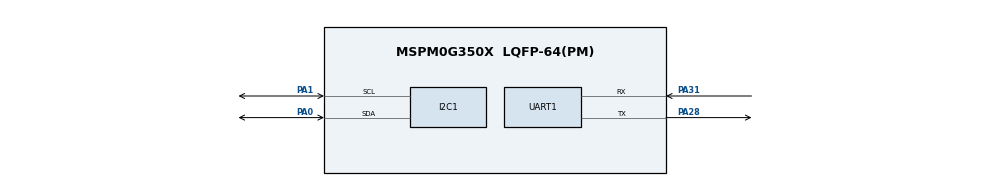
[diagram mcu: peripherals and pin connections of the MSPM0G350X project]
/**
 *
 * @cliArgs --device "MSPM0G350X" --part "Default" --package "LQFP-64(PM)" --product "mspm0_sdk@2.05.01.00"
 * @versions {"tool":"1.28.0+4696"}
 */

/**
 * Import the modules used in this configuration.
 */
const ADC12  = scripting.addModule("/ti/driverlib/ADC12", {}, false);
const ADC121 = ADC12.addInstance();
const GPIO   = scripting.addModule("/ti/driverlib/GPIO", {}, false);
const GPIO1  = GPIO.addInstance();
const GPIO2  = GPIO.addInstance();
const GPIO3  = GPIO.addInstance();
const GPIO4  = GPIO.addInstance();
const GPIO5  = GPIO.addInstance();
const GPIO6  = GPIO.addInstance();
const I2C    = scripting.addModule("/ti/driverlib/I2C", {}, false);
const I2C1   = I2C.addInstance();
const SYSCTL = scripting.addModule("/ti/driverlib/SYSCTL");
const TIMER  = scripting.addModule("/ti/driverlib/TIMER", {}, false);
const TIMER1 = TIMER.addInstance();
const UART   = scripting.addModule("/ti/driverlib/UART", {}, false);
const UART1  = UART.addInstance();

/**
 * Write custom configuration values to the imported modules.
 */
ADC121.$name                             = "ADC_VOLTAGE";
ADC121.sampClkDiv                        = "DL_ADC12_CLOCK_DIVIDE_8";
ADC121.adcMem0_name                      = "ADC_CH0";
ADC121.powerDownMode                     = "DL_ADC12_POWER_DOWN_MODE_MANUAL";
ADC121.sampleTime0                       = "1us";
ADC121.trigSrc                           = "DL_ADC12_TRIG_SRC_EVENT";
ADC121.subChanID                         = 1;
ADC121.peripheral.$assign                = "ADC1";
ADC121.peripheral.adcPin0.$assign        = "PA15";
ADC121.adcPin0Config.$name               = "ti_driverlib_gpio_GPIOPinGeneric0";
ADC121.adcPin0Config.hideOutputInversion = scripting.forceWrite(false);
ADC121.adcPin0Config.enableConfig        = true;

const Board = scripting.addModule("/ti/driverlib/Board", {}, false);

/* 4-bit address switch: bit0=PB26, bit1=PA25, bit2=PA23, bit3=PB23.
 * Spans PORTA and PORTB, so it is split into two GPIO instances
 * (one instance can only belong to one port). */
GPIO1.$name                              = "ADDR_SW_B";
GPIO1.port                               = "PORTB";
GPIO1.associatedPins.create(2);
GPIO1.associatedPins[0].$name            = "PIN_B26";
GPIO1.associatedPins[0].direction        = "INPUT";
GPIO1.associatedPins[0].internalResistor = "PULL_UP";
GPIO1.associatedPins[0].assignedPin      = "26";
GPIO1.associatedPins[1].$name            = "PIN_B23";
GPIO1.associatedPins[1].direction        = "INPUT";
GPIO1.associatedPins[1].internalResistor = "PULL_UP";
GPIO1.associatedPins[1].assignedPin      = "23";

const GPIO7 = GPIO.addInstance();
GPIO7.$name                              = "ADDR_SW_A";
GPIO7.port                               = "PORTA";
GPIO7.associatedPins.create(2);
GPIO7.associatedPins[0].$name            = "PIN_A25";
GPIO7.associatedPins[0].direction        = "INPUT";
GPIO7.associatedPins[0].internalResistor = "PULL_UP";
GPIO7.associatedPins[0].assignedPin      = "25";
GPIO7.associatedPins[1].$name            = "PIN_A23";
GPIO7.associatedPins[1].direction        = "INPUT";
GPIO7.associatedPins[1].internalResistor = "PULL_UP";
GPIO7.associatedPins[1].assignedPin      = "23";

GPIO2.$name                          = "RELAY_PA07";
GPIO2.port                           = "PORTA";
GPIO2.associatedPins[0].$name        = "PIN_7";
GPIO2.associatedPins[0].initialValue = "SET";
GPIO2.associatedPins[0].assignedPin  = "7";

GPIO3.$name                              = "BT_DETECT";
GPIO3.associatedPins[0].$name            = "PIN_4";
GPIO3.associatedPins[0].direction        = "INPUT";
GPIO3.associatedPins[0].internalResistor = "PULL_UP";

GPIO4.$name                          = "OLED_PWR";
GPIO4.port                           = "PORTA";
GPIO4.associatedPins[0].$name        = "PIN_8";
GPIO4.associatedPins[0].initialValue = "SET";
GPIO4.associatedPins[0].assignedPin  = "16";

GPIO5.$name                          = "RELAY_PA09";
GPIO5.port                           = "PORTA";
GPIO5.associatedPins[0].$name        = "PIN_9";
GPIO5.associatedPins[0].initialValue = "SET";
GPIO5.associatedPins[0].assignedPin  = "9";

GPIO6.$name                          = "BT_PWR";
GPIO6.associatedPins[0].$name        = "PIN_6";
GPIO6.associatedPins[0].initialValue = "SET";
GPIO6.associatedPins[0].assignedPin  = "30";

I2C1.basicEnableController             = true;
I2C1.basicControllerStandardBusSpeed   = "Fast";
I2C1.$name                             = "I2C_OLED";
I2C1.peripheral.$assign                = "I2C0";
I2C1.peripheral.sdaPin.$assign         = "PA0";
I2C1.peripheral.sclPin.$assign         = "PA1";
I2C1.sdaPinConfig.hideOutputInversion  = scripting.forceWrite(false);
I2C1.sdaPinConfig.onlyInternalResistor = scripting.forceWrite(false);
I2C1.sdaPinConfig.passedPeripheralType = scripting.forceWrite("Digital");
I2C1.sdaPinConfig.$name                = "ti_driverlib_gpio_GPIOPinGeneric3";
I2C1.sclPinConfig.hideOutputInversion  = scripting.forceWrite(false);
I2C1.sclPinConfig.onlyInternalResistor = scripting.forceWrite(false);
I2C1.sclPinConfig.passedPeripheralType = scripting.forceWrite("Digital");
I2C1.sclPinConfig.$name                = "ti_driverlib_gpio_GPIOPinGeneric4";

SYSCTL.forceDefaultClkConfig = true;

TIMER1.timerMode                   = "PERIODIC";
TIMER1.event1PublisherChannel      = 1;
TIMER1.event1ControllerInterruptEn = ["ZERO_EVENT"];
TIMER1.timerPeriod                 = "39.06us";
TIMER1.$name                       = "TIMER_ADC_INST";

UART1.$name                    = "UART_0";
UART1.peripheral.rxPin.$assign = "PA31";
UART1.peripheral.txPin.$assign = "PA28";
UART1.txPinConfig.$name        = "ti_driverlib_gpio_GPIOPinGeneric1";
UART1.rxPinConfig.$name        = "ti_driverlib_gpio_GPIOPinGeneric2";

/**
 * Pinmux solution for unlocked pins/peripherals. This ensures that minor changes to the automatic solver in a future
 * version of the tool will not impact the pinmux you originally saw.  These lines can be completely deleted in order to
 * re-solve from scratch.
 */
Board.peripheral.$suggestSolution            = "DEBUGSS";
Board.peripheral.swclkPin.$suggestSolution   = "PA20";
Board.peripheral.swdioPin.$suggestSolution   = "PA19";
GPIO3.associatedPins[0].pin.$suggestSolution = "PB13";
GPIO1.associatedPins[0].pin.$suggestSolution = "PB26";
GPIO1.associatedPins[1].pin.$suggestSolution = "PB23";
GPIO2.associatedPins[0].pin.$suggestSolution = "PA7";
GPIO4.associatedPins[0].pin.$suggestSolution = "PA16";
GPIO6.associatedPins[0].pin.$suggestSolution = "PA30";
GPIO7.associatedPins[0].pin.$suggestSolution = "PA25";
GPIO7.associatedPins[1].pin.$suggestSolution = "PA23";
GPIO5.associatedPins[0].pin.$suggestSolution = "PA9";
SYSCTL.peripheral.$suggestSolution           = "SYSCTL";
TIMER1.peripheral.$suggestSolution           = "TIMA0";
UART1.peripheral.$suggestSolution            = "UART0";
